# ESP32-C6 register map
Vendor: ESPRESSIF SYSTEMS (SHANGHAI) CO., LTD.; Series: ESP32 C-Series; File version: 12
CPU: RV32IMAC r0p0, little endian, no MPU, no FPU, 0 interrupt priority bits
Address unit: 32 bits
Registers are 32-bit, read-write, reset 0x0 unless marked. A register's access mark holds for its fields unless they carry their own. Offsets are from the block's base; [hi:lo] are bit positions.

## PARL_IO — Parallel IO Controller
Base 0x60015000
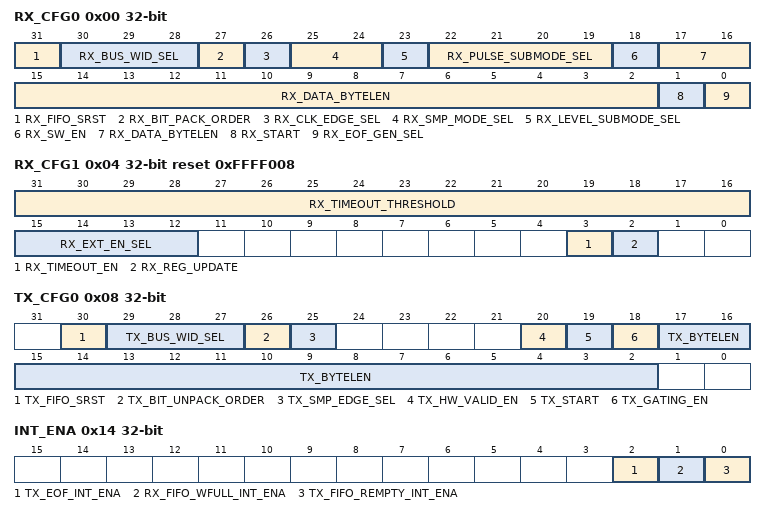
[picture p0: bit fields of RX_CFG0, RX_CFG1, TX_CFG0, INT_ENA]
0x00 RX_CFG0 — Parallel RX module configuration register0.
  [31] RX_FIFO_SRST — Write 1 to enable soft reset of async fifo in rx module.
  [30:28] RX_BUS_WID_SEL — Rx data bus width selection. 100: bus width is 1 bit 011: bus width is 2 bits 010: bus width is 4 bits 001: bus width is 8 bits 000: bus width is 16 bits
  [27] RX_BIT_PACK_ORDER — Write 0 to pack bits into 1byte from MSB when data bus width is 4/2/1 bits. Write 0 to pack bits into 1byte from LSB when data bus width is 4/2/1 bits.
  [26] RX_CLK_EDGE_SEL — Write 0 to enable sampling data on the rising edge of rx clock. Write 0 to enable sampling data on the falling edge of rx clock.
  [25:24] RX_SMP_MODE_SEL — Rx data sampling mode selection. 000: external level enable mode 001: external pulse enable mode 010: internal software enable mode
  [23] RX_LEVEL_SUBMODE_SEL — Write 0 to sample data at high level of external enable signal. Write 1 to sample data at low level of external enable signal.
  [22:19] RX_PULSE_SUBMODE_SEL — Pulse submode selection. 0000: positive pulse start(data bit included) && positive pulse end(data bit included) 0001: positive pulse start(data bit included) && positive pulse end (data bit excluded) 0010: positive pulse start(data bit excluded) && positive pulse end (data bit included) 0011: positive pulse start(data bit excluded) && positive pulse end (data bit excluded) 0100: positive pulse start(data bit included) && length end 0101: positive pulse start(data bit excluded) && length end 0110: negative pulse start(data bit included) && negative pulse end(data bit included) 0111: negative pulse start(data bit included) && negative pulse end (data bit excluded) 1000: negative pulse start(data bit excluded) && negative pulse end (data bit included) 1001: negative pulse start(data bit excluded) && negative pulse end (data bit excluded) 1010: negative pulse start(data bit included) && length end 1011: negative pulse start(data bit excluded) && length end
  [18] RX_SW_EN — Write 1 to enable software data sampling.
  [17:2] RX_DATA_BYTELEN — Configures rx receieved data byte length.
  [1] RX_START — Write 1 to start rx global data sampling.
  [0] RX_EOF_GEN_SEL — Write 0 to select eof generated manchnism by configured data byte length. Write 1 to select eof generated manchnism by external enable signal.
0x04 RX_CFG1 access per field reset 0xFFFF008 — Parallel RX module configuration register1.
  [31:16] RX_TIMEOUT_THRESHOLD rw — Configures rx threshold of timeout counter.
  [15:12] RX_EXT_EN_SEL rw — Configures rx external enable signal selection from 16 data lines.
  [3] RX_TIMEOUT_EN rw — Write 1 to enable timeout count to generate error eof.
  [2] RX_REG_UPDATE wo — Write 1 to update rx register configuration signals.
0x08 TX_CFG0 — Parallel TX module configuration register0.
  [30] TX_FIFO_SRST — Write 1 to enable soft reset of async fifo in tx module.
  [29:27] TX_BUS_WID_SEL — Tx data bus width selection. 100: bus width is 1 bit 011: bus width is 2 bits 010: bus width is 4 bits 001: bus width is 8 bits 000: bus width is 16 bits
  [26] TX_BIT_UNPACK_ORDER — Write 0 to unpack bits from 1byte from MSB when data bus width is 4/2/1 bits. Write 0 to unpack bits from 1byte from LSB when data bus width is 4/2/1 bits.
  [25] TX_SMP_EDGE_SEL — Write 0 to enable sampling data on the rising edge of tx clock. Write 0 to enable sampling data on the falling edge of tx clock.
  [20] TX_HW_VALID_EN — Write 1 to enable tx hardware data valid signal.
  [19] TX_START — Write 1 to start tx global data output.
  [18] TX_GATING_EN — Write 1 to enable output tx clock gating.
  [17:2] TX_BYTELEN — Configures tx sending data byte length.
0x0C TX_CFG1 — Parallel TX module configuration register1.
  [31:16] TX_IDLE_VALUE — Configures data value on tx bus when IDLE state.
0x10 ST ro — Parallel IO module status register0.
  [31] TX_READY — Represents the status that tx is ready.
0x14 INT_ENA — Parallel IO interrupt enable singal configuration register.
  [2] TX_EOF_INT_ENA — Write 1 to enable TX_EOF_INTR.
  [1] RX_FIFO_WFULL_INT_ENA — Write 1 to enable RX_FIFO_WFULL_INTR.
  [0] TX_FIFO_REMPTY_INT_ENA — Write 1 to enable TX_FIFO_REMPTY_INTR.
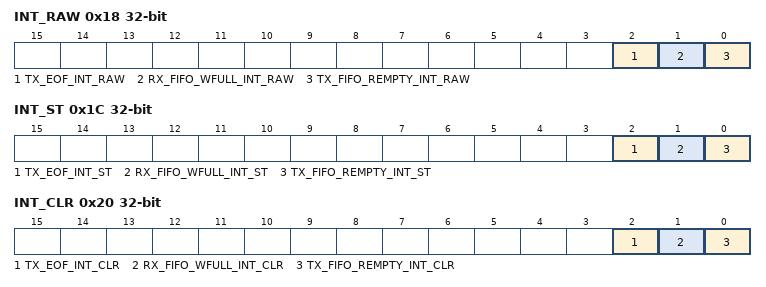
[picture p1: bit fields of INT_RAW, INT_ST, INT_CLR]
0x18 INT_RAW — Parallel IO interrupt raw singal status register.
  [2] TX_EOF_INT_RAW — The raw interrupt status of TX_EOF_INTR.
  [1] RX_FIFO_WFULL_INT_RAW — The raw interrupt status of RX_FIFO_WFULL_INTR.
  [0] TX_FIFO_REMPTY_INT_RAW — The raw interrupt status of TX_FIFO_REMPTY_INTR.
0x1C INT_ST ro — Parallel IO interrupt singal status register.
  [2] TX_EOF_INT_ST — The masked interrupt status of TX_EOF_INTR.
  [1] RX_FIFO_WFULL_INT_ST — The masked interrupt status of RX_FIFO_WFULL_INTR.
  [0] TX_FIFO_REMPTY_INT_ST — The masked interrupt status of TX_FIFO_REMPTY_INTR.
0x20 INT_CLR wo — Parallel IO interrupt clear singal configuration register.
  [2] TX_EOF_INT_CLR — Write 1 to clear TX_EOF_INTR.
  [1] RX_FIFO_WFULL_INT_CLR — Write 1 to clear RX_FIFO_WFULL_INTR.
  [0] TX_FIFO_REMPTY_INT_CLR — Write 1 to clear TX_FIFO_REMPTY_INTR.
0x120 CLK — Parallel IO clk configuration register
  [0] EN — Force clock on for this register file
0x3FC VERSION reset 0x2202240
  [27:0] DATE — Version of this register file
